# LKS32MC08x register map
Vendor: Linko Ltd.; Series: LKS32MC08x; File version: 1.0
CPU: CM0 r1p0, little endian, MPU, no FPU, 3 interrupt priority bits
Registers are 32-bit, read-write, reset 0x0 unless marked. A register's access mark holds for its fields unless they carry their own. Offsets are from the block's base; [hi:lo] are bit positions; {n}, {i} and the like mark numbered series; 'fields as' and 'values as' point back to an identical list.

## ADC0 — ADC0 registers
Base 0x40011400
{0x0+4i} ADC0_DAT{i} (i=0..19) — ADC0 data{i}
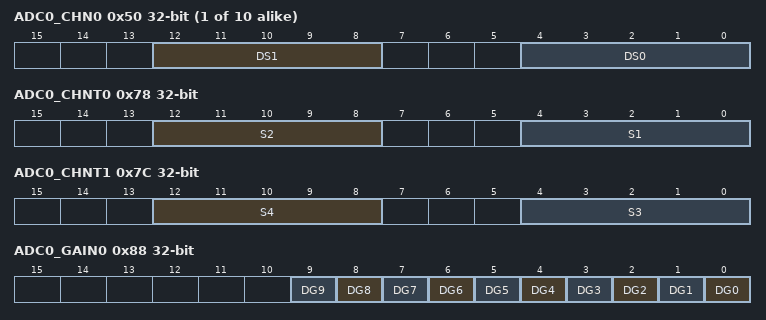
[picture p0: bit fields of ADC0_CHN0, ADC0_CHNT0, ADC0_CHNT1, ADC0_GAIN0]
{0x50+4i} ADC0_CHN{i} (i=0..9) — ADC0 data{2i}/{2i+1} source
  [12:8] DS{2i+1} — Data{2i+1} source
    {v}=OPA{v}_OUT (v=0..3); {v}=ADC_CH{v} (v=4..17); 18=Temp; 19=VSS
  [4:0] DS{2i} — Data{2i} source
    values as DS{2i+1}
0x78 ADC0_CHNT0 — ADC0 channel numbers 0
  [12:8] S2 — 2nd segment sample times
  [4:0] S1 — 1st segment sample times
0x7C ADC0_CHNT1 — ADC0 channel numbers 1
  [12:8] S4 — 4th segment sample times
  [4:0] S3 — 3rd segment sample times
0x80 ADC0_SD0 — ADC0 channel 0~9 single/differential
0x84 ADC0_SD1 — ADC0 channel 10~19 single/differential
0x88 ADC0_GAIN0 — ADC0 channel 0~9 gain selection
  [n] DG{n} (n=0..9) — Data{n} gain selection
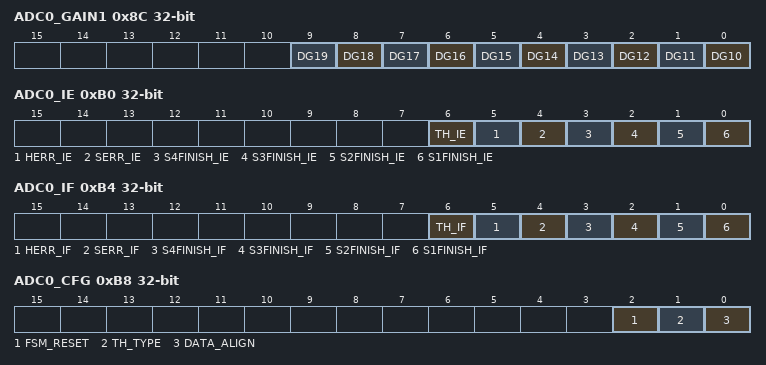
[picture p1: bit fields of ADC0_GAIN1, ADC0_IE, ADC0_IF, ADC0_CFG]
0x8C ADC0_GAIN1 — ADC0 channel 10~19 gain selection
  [n-10] DG{n} (n=10..19) — Data{n} gain selection
0x90 ADC0_DC_A0 — ADC0 DC offset of sample circuit A for low gain
  [15:0] DC_OFFSET — DC offset value
0x94 ADC0_DC_A1 — ADC0 DC offset of sample circuit A for high gain
  [15:0] DC_OFFSET — DC offset value
0x98 ADC0_AMC_A0 — ADC0 amplification calibration of sample circuit A for low gain
  [9:0] AM_CALI — Amplification calibration value
0x9C ADC0_AMC_A1 — ADC0 amplification calibration of sample circuit A for high gain
  [9:0] AM_CALI — Amplification calibration value
0xA0 ADC0_DC_B0 — ADC0 DC offset of sample circuit A for low gain
  [15:0] DC_OFFSET — DC offset value
0xA4 ADC0_DC_B1 — ADC0 DC offset of sample circuit A for high gain
  [15:0] DC_OFFSET — DC offset value
0xA8 ADC0_AMC_B0 — ADC0 amplification calibration of sample circuit A for low gain
  [9:0] AM_CALI — Amplification calibration value
0xAC ADC0_AMC_B1 — ADC0 amplification calibration of sample circuit A for high gain
  [9:0] AM_CALI — Amplification calibration value
0xB0 ADC0_IE — ADC0 interrupt enable
  [6] TH_IE — ADC_DAT0 Threshold reached interrupt enable
  [5] HERR_IE — Hardware trigger error interrupt enable
  [4] SERR_IE — Software trigger error interrupt enable
  [3] S4FINISH_IE — 4th segment sample finish interrupt enable
  [2] S3FINISH_IE — 3rd segment sample finish interrupt enable
  [1] S2FINISH_IE — 2nd segment sample finish interrupt enable
  [0] S1FINISH_IE — 1st segment sample finish interrupt enable
0xB4 ADC0_IF — ADC0 interrupt flag
  [6] TH_IF — ADC_DAT0 Threshold reached
  [5] HERR_IF — Hardware trigger error interrupt, write 1 to clear
  [4] SERR_IF — Software trigger error interrupt, write 1 to clear
  [3] S4FINISH_IF — 4th segment sample finish interrupt, write 1 to clear
  [2] S3FINISH_IF — 3rd segment sample finish interrupt, write 1 to clear
  [1] S2FINISH_IF — 2nd segment sample finish interrupt, write 1 to clear
  [0] S1FINISH_IF — 1st segment sample finish interrupt, write 1 to clear
0xB8 ADC0_CFG — ADC0 configuration
  [2] FSM_RESET — sample state machine reset
  [1] TH_TYPE — ADC_TH0 high/low
    0=low (low threshold); 1=high threshold
  [0] DATA_ALIGN — ADC data alignment
    0=LEFT (left alignment, padding with 4'b0); 1=RIGHT (right alignment, sign bit extension at head)
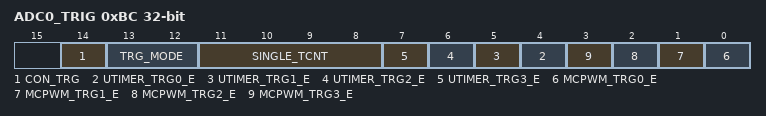
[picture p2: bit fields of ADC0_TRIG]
0xBC ADC0_TRIG — ADC0 sample trigger config
  [14] CON_TRG — Continuous trigger mode
  [13:12] TRG_MODE — trigger mode
  [11:8] SINGLE_TCNT — single segment trigger counter
  [n+4] UTIMER_TRG{n}_E (n=0..3) — UTIMER trigger{n} enable
    0=Disabled (UTIMER trigger {n} disabled); 1=Enabled (UTIMER trigger {n} enabled)
  [n] MCPWM_TRG{n}_E (n=0..3) — MCPWM trigger{n} enable
    0=Disabled (MCPWM trigger {n} disabled); 1=Enabled (MCPWM trigger {n} enabled)
0xC0 ADC0_SWT wo — ADC0 software trigger
  [15:0] SWT — write 0x5AA5 to trigger ADC sample
0xC4 ADC0_DAT0_TH — ADC0 DAT0 threshold
  [15:0] DAT0_TH — ADC data0 threshold
